# CAM_PRM register map
Vendor: Texas Instruments
Peripheral module from a debugger description file (folder omap4460).
Registers are 32-bit, access not given, reset 0x101 unless marked. A register's access mark holds for its fields unless they carry their own. Offsets are as the file gives them; lines under a group give offsets from that group; [hi:lo] are bit positions; {n}, {i} and the like mark numbered series; 'fields as' and 'values as' point back to an identical list; <NAME> marks a mode.

## CAM_PRM
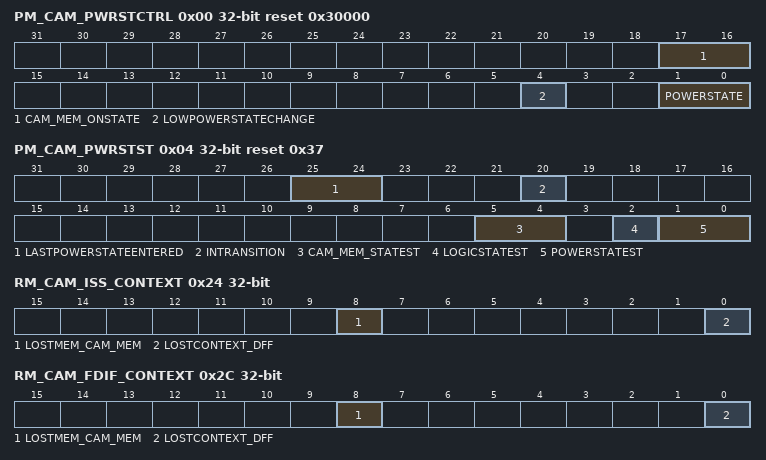
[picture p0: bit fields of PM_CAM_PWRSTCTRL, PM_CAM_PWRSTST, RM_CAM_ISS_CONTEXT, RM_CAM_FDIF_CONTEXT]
0x00 PM_CAM_PWRSTCTRL reset 0x30000 — This register controls the CAM power state to reach upon a domain sleep transition
  [17:16] CAM_MEM_ONSTATE — CAM_MEM memory state when domain is ON. (access R Rreturns1s)
    3=CAM_MEM_ONSTATE_3_r (Memory bank is on when the domain is ON.)
  [4] LOWPOWERSTATECHANGE — Power state change request when domain has already performed a sleep transition. Allows going into deeper low power state without waking up the power domain. (access RW WSpecial)
    0=Do not request a low power state change; 1=Request a low power state change. This bit is automatically cleared when the power state is effectively changed or when power state is ON.
  [1:0] POWERSTATE rw — Power state control
    0=OFF state; 1=POWERSTATE_1_r (Reserved); 2=INACTIVE state; 3=ON State
0x04 PM_CAM_PWRSTST reset 0x37 — This register provides a status on the current CAM power domain state. [warm reset insensitive]
  [25:24] LASTPOWERSTATEENTERED — Last low power state entered. Set to 0x3 upon write of the same only. This register is intended for debug purpose only. (access RW W1toSet)
    3=LASTPOWERSTATEENTERED_3_r (Power domain was previously ON-ACTIVE); 2=LASTPOWERSTATEENTERED_2_r (Power domain was previously ON-INACTIVE); 1=LASTPOWERSTATEENTERED_1_r (Power domain was previously in RETENTION); 0=LASTPOWERSTATEENTERED_0_r (Power domain was previously OFF)
  [20] INTRANSITION ro — Domain transition status
    1=INTRANSITION_1_r (Power domain transition is in progress.); 0=INTRANSITION_0_r (No on-going transition on power domain)
  [5:4] CAM_MEM_STATEST ro — CAM_MEM memory state status
    3=CAM_MEM_STATEST_3_r (Memory is ON); 2=CAM_MEM_STATEST_2_r (Reserved); 1=CAM_MEM_STATEST_1_r (Reserved); 0=CAM_MEM_STATEST_0_r (Memory is OFF)
  [2] LOGICSTATEST ro — Logic state status
    1=LOGICSTATEST_1_r (Logic in domain is ON); 0=LOGICSTATEST_0_r (Logic in domain is OFF)
  [1:0] POWERSTATEST ro — Current power state status
    3=POWERSTATEST_3_r (Power domain is ON-ACTIVE); 2=POWERSTATEST_2_r (Power domain is ON-INACTIVE); 1=POWERSTATEST_1_r (Power domain is in RETENTION); 0=POWERSTATEST_0_r (Power domain is OFF)
0x24 RM_CAM_ISS_CONTEXT — This register contains dedicated ISS context statuses. [warm reset insensitive]
  [8] LOSTMEM_CAM_MEM — Specify if memory-based context in CAM_MEM memory bank has been lost due to a previous power transition or other reset source. (access RW W1toClr)
    0=Context has been maintained; 1=Context has been lost
  [0] LOSTCONTEXT_DFF — Specify if DFF-based context has been lost due to a previous power transition or other reset source. (set upon assertion of CAM_RST signal) (access RW W1toClr)
    0=Context has been maintained; 1=Context has been lost
0x2C RM_CAM_FDIF_CONTEXT — This register contains dedicated FDIF context statuses. [warm reset insensitive]
  fields as RM_CAM_ISS_CONTEXT
